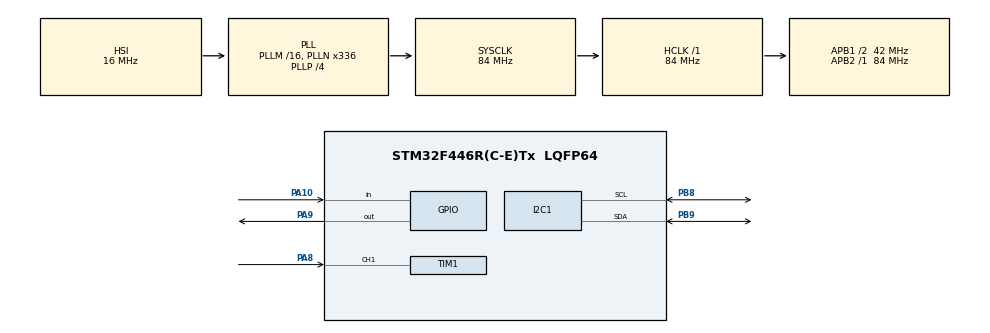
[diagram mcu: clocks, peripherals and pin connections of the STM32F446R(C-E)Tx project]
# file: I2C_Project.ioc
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FREERTOS.Mutexes01=I2CMutex,Dynamic,NULL
FREERTOS.Tasks01=defaultTask,0,128,StartDefaultTask,Default,NULL,Dynamic,NULL,NULL;IrReadTask,0,128,IRTask_Start,Default,NULL,Dynamic,NULL,NULL;I2CSendTask,-3,128,I2CSendTask_Start,Default,NULL,Dynamic,NULL,NULL
I2C1.OwnAddress=0x10
Mcu.Family=STM32F4
Mcu.Name=STM32F446R(C-E)Tx
Mcu.Package=LQFP64
NVIC.I2C1_ER_IRQn=true\:5\:0\:false\:false\:true\:true\:true\:true
NVIC.I2C1_EV_IRQn=true\:5\:0\:false\:false\:true\:true\:true\:true
NVIC.PriorityGroup=NVIC_PRIORITYGROUP_4
NVIC.TIM1_CC_IRQn=true\:5\:0\:false\:false\:true\:true\:true\:true
NVIC.TIM2_IRQn=true\:15\:0\:false\:false\:true\:false\:false\:true
NVIC.TimeBase=TIM2_IRQn
NVIC.TimeBaseIP=TIM2
PA10.Signal=GPIO_Input
PA13.GPIO_Label=TMS
PA13.Mode=Serial_Wire
PA13.Signal=SYS_JTMS-SWDIO
PA14.GPIO_Label=TCK
PA14.Mode=Serial_Wire
PA14.Signal=SYS_JTCK-SWCLK
PA2.GPIO_Label=USART_TX
PA2.Signal=USART2_TX
PA3.GPIO_Label=USART_RX
PA3.Signal=USART2_RX
PA8.Signal=S_TIM1_CH1
PA9.Signal=GPIO_Output
PB3.GPIO_Label=SWO
PB3.Signal=SYS_JTDO-SWO
PB8.Mode=I2C
PB8.Signal=I2C1_SCL
PB9.Mode=I2C
PB9.Signal=I2C1_SDA
PC14-OSC32_IN.Mode=LSE-External-Oscillator
PC14-OSC32_IN.Signal=RCC_OSC32_IN
PC15-OSC32_OUT.Mode=LSE-External-Oscillator
PC15-OSC32_OUT.Signal=RCC_OSC32_OUT
PH0-OSC_IN.Mode=HSE-External-Oscillator
PH0-OSC_IN.Signal=RCC_OSC_IN
PH1-OSC_OUT.Mode=HSE-External-Oscillator
PH1-OSC_OUT.Signal=RCC_OSC_OUT
ProjectManager.HeapSize=0x200
ProjectManager.StackSize=0x400
ProjectManager.TargetToolchain=STM32CubeIDE
RCC.AHBFreq_Value=84000000
RCC.APB1CLKDivider=RCC_HCLK_DIV2
RCC.APB1Freq_Value=42000000
RCC.APB1TimFreq_Value=84000000
RCC.APB2Freq_Value=84000000
RCC.APB2TimFreq_Value=84000000
RCC.CortexFreq_Value=84000000
RCC.FLatency-AdvancedSettings=FLASH_LATENCY_2
RCC.HCLKFreq_Value=84000000
RCC.HSE_VALUE=8000000
RCC.HSI_VALUE=16000000
RCC.PLLN=336
RCC.PLLP=RCC_PLLP_DIV4
RCC.SYSCLKFreq_VALUE=84000000
RCC.SYSCLKSource=RCC_SYSCLKSOURCE_PLLCLK
RCC.USBFreq_Value=168000000
RCC.VCOOutputFreq_Value=336000000
SH.S_TIM1_CH1.0=TIM1_CH1,Input_Capture1_from_TI1
TIM1.Channel-Input_Capture1_from_TI1=TIM_CHANNEL_1
TIM1.Prescaler=84
VP_FREERTOS_VS_CMSIS_V1.Mode=CMSIS_V1
VP_SYS_VS_tim2.Mode=TIM2
board=NUCLEO-F446RE

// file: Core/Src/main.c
#include "main.h"
#include "cmsis_os.h"

I2C_HandleTypeDef hi2c1;

TIM_HandleTypeDef htim1;

osThreadId defaultTaskHandle;
osThreadId IrReadTaskHandle;
osThreadId I2CSendTaskHandle;
osMutexId I2CMutexHandle;

#define TXBUFSIZE 1
volatile uint8_t rx_buf;
uint8_t tx_buf=0;

HAL_StatusTypeDef sig = 0x0;
void ResetI2C(I2C_HandleTypeDef* rev_i2c)
{
	HAL_I2C_DeInit(rev_i2c);
	HAL_I2C_Init(rev_i2c);
}

void SystemClock_Config(void);
static void MX_GPIO_Init(void);
static void MX_I2C1_Init(void);
static void MX_TIM1_Init(void);
void StartDefaultTask(void const * argument);
void IRTask_Start(void const * argument);
void I2CSendTask_Start(void const * argument);

int main(void)
{

  HAL_Init();

  SystemClock_Config();

  MX_GPIO_Init();
  MX_I2C1_Init();
  MX_TIM1_Init();

  osMutexDef(I2CMutex);
  I2CMutexHandle = osMutexCreate(osMutex(I2CMutex));

  osThreadDef(defaultTask, StartDefaultTask, osPriorityNormal, 0, 128);
  defaultTaskHandle = osThreadCreate(osThread(defaultTask), NULL);

  /* definition and creation of IrReadTask */
  osThreadDef(IrReadTask, IRTask_Start, osPriorityNormal, 0, 128);
  IrReadTaskHandle = osThreadCreate(osThread(IrReadTask), NULL);

  /* definition and creation of I2CSendTask */
  osThreadDef(I2CSendTask, I2CSendTask_Start, osPriorityNormal, 0, 128);
  I2CSendTaskHandle = osThreadCreate(osThread(I2CSendTask), NULL);

  /* Start scheduler */
  osKernelStart();

  while (1)
  {

  }

}

void SystemClock_Config(void)
{
  RCC_OscInitTypeDef RCC_OscInitStruct = {0};
  RCC_ClkInitTypeDef RCC_ClkInitStruct = {0};

  /** Configure the main internal regulator output voltage
  */
  __HAL_RCC_PWR_CLK_ENABLE();
  __HAL_PWR_VOLTAGESCALING_CONFIG(PWR_REGULATOR_VOLTAGE_SCALE3);
  /** Initializes the RCC Oscillators according to the specified parameters
  * in the RCC_OscInitTypeDef structure.
  */
  RCC_OscInitStruct.OscillatorType = RCC_OSCILLATORTYPE_HSI;
  RCC_OscInitStruct.HSIState = RCC_HSI_ON;
  RCC_OscInitStruct.HSICalibrationValue = RCC_HSICALIBRATION_DEFAULT;
  RCC_OscInitStruct.PLL.PLLState = RCC_PLL_ON;
  RCC_OscInitStruct.PLL.PLLSource = RCC_PLLSOURCE_HSI;
  RCC_OscInitStruct.PLL.PLLM = 16;
  RCC_OscInitStruct.PLL.PLLN = 336;
  RCC_OscInitStruct.PLL.PLLP = RCC_PLLP_DIV4;
  RCC_OscInitStruct.PLL.PLLQ = 2;
  RCC_OscInitStruct.PLL.PLLR = 2;
  if (HAL_RCC_OscConfig(&RCC_OscInitStruct) != HAL_OK)
  {
    Error_Handler();
  }
  /** Initializes the CPU, AHB and APB buses clocks
  */
  RCC_ClkInitStruct.ClockType = RCC_CLOCKTYPE_HCLK|RCC_CLOCKTYPE_SYSCLK
                              |RCC_CLOCKTYPE_PCLK1|RCC_CLOCKTYPE_PCLK2;
  RCC_ClkInitStruct.SYSCLKSource = RCC_SYSCLKSOURCE_PLLCLK;
  RCC_ClkInitStruct.AHBCLKDivider = RCC_SYSCLK_DIV1;
  RCC_ClkInitStruct.APB1CLKDivider = RCC_HCLK_DIV2;
  RCC_ClkInitStruct.APB2CLKDivider = RCC_HCLK_DIV1;

  if (HAL_RCC_ClockConfig(&RCC_ClkInitStruct, FLASH_LATENCY_2) != HAL_OK)
  {
    Error_Handler();
  }
}

static void MX_I2C1_Init(void)
{

  hi2c1.Instance = I2C1;
  hi2c1.Init.ClockSpeed = 100000;
  hi2c1.Init.DutyCycle = I2C_DUTYCYCLE_2;
  hi2c1.Init.OwnAddress1 = 32;
  hi2c1.Init.AddressingMode = I2C_ADDRESSINGMODE_7BIT;
  hi2c1.Init.DualAddressMode = I2C_DUALADDRESS_DISABLE;
  hi2c1.Init.OwnAddress2 = 0;
  hi2c1.Init.GeneralCallMode = I2C_GENERALCALL_DISABLE;
  hi2c1.Init.NoStretchMode = I2C_NOSTRETCH_DISABLE;
  if (HAL_I2C_Init(&hi2c1) != HAL_OK)
  {
    Error_Handler();
  }

}

static void MX_TIM1_Init(void)
{

  TIM_MasterConfigTypeDef sMasterConfig = {0};
  TIM_IC_InitTypeDef sConfigIC = {0};

  htim1.Instance = TIM1;
  htim1.Init.Prescaler = 84;
  htim1.Init.CounterMode = TIM_COUNTERMODE_UP;
  htim1.Init.Period = 65535;
  htim1.Init.ClockDivision = TIM_CLOCKDIVISION_DIV1;
  htim1.Init.RepetitionCounter = 0;
  htim1.Init.AutoReloadPreload = TIM_AUTORELOAD_PRELOAD_DISABLE;
  if (HAL_TIM_IC_Init(&htim1) != HAL_OK)
  {
    Error_Handler();
  }
  sMasterConfig.MasterOutputTrigger = TIM_TRGO_RESET;
  sMasterConfig.MasterSlaveMode = TIM_MASTERSLAVEMODE_DISABLE;
  if (HAL_TIMEx_MasterConfigSynchronization(&htim1, &sMasterConfig) != HAL_OK)
  {
    Error_Handler();
  }
  sConfigIC.ICPolarity = TIM_INPUTCHANNELPOLARITY_RISING;
  sConfigIC.ICSelection = TIM_ICSELECTION_DIRECTTI;
  sConfigIC.ICPrescaler = TIM_ICPSC_DIV1;
  sConfigIC.ICFilter = 0;
  if (HAL_TIM_IC_ConfigChannel(&htim1, &sConfigIC, TIM_CHANNEL_1) != HAL_OK)
  {
    Error_Handler();
  }

}

static void MX_GPIO_Init(void)
{
  GPIO_InitTypeDef GPIO_InitStruct = {0};

  /* GPIO Ports Clock Enable */
  __HAL_RCC_GPIOC_CLK_ENABLE();
  __HAL_RCC_GPIOH_CLK_ENABLE();
  __HAL_RCC_GPIOA_CLK_ENABLE();
  __HAL_RCC_GPIOB_CLK_ENABLE();

  /*Configure GPIO pin Output Level */
  HAL_GPIO_WritePin(GPIOA, GPIO_PIN_9, GPIO_PIN_RESET);

  /*Configure GPIO pins : USART_TX_Pin USART_RX_Pin */
  GPIO_InitStruct.Pin = USART_TX_Pin|USART_RX_Pin;
  GPIO_InitStruct.Mode = GPIO_MODE_AF_PP;
  GPIO_InitStruct.Pull = GPIO_NOPULL;
  GPIO_InitStruct.Speed = GPIO_SPEED_FREQ_VERY_HIGH;
  GPIO_InitStruct.Alternate = GPIO_AF7_USART2;
  HAL_GPIO_Init(GPIOA, &GPIO_InitStruct);

  /*Configure GPIO pin : PA9 */
  GPIO_InitStruct.Pin = GPIO_PIN_9;
  GPIO_InitStruct.Mode = GPIO_MODE_OUTPUT_PP;
  GPIO_InitStruct.Pull = GPIO_NOPULL;
  GPIO_InitStruct.Speed = GPIO_SPEED_FREQ_LOW;
  HAL_GPIO_Init(GPIOA, &GPIO_InitStruct);

  /*Configure GPIO pin : PA10 */
  GPIO_InitStruct.Pin = GPIO_PIN_10;
  GPIO_InitStruct.Mode = GPIO_MODE_INPUT;
  GPIO_InitStruct.Pull = GPIO_NOPULL;
  HAL_GPIO_Init(GPIOA, &GPIO_InitStruct);

}

/* USER CODE END Header_StartDefaultTask */
void StartDefaultTask(void const * argument)
{
  for(;;)
  {
    osDelay(1);
  }
}

void IRTask_Start(void const * argument)
{
  HAL_TIM_IC_Start_IT(&htim1, TIM_CHANNEL_1);
  for(;;)
  {
	  xSemaphoreTake(I2CMutexHandle,portMAX_DELAY);
	  if(HAL_GPIO_ReadPin(GPIOA, GPIO_PIN_10))
	  {
		tx_buf=0;
	  }
	  else
	  {
		  tx_buf=1;
	  }
	  xSemaphoreGive(I2CMutexHandle);
    osDelay(20);
  }
  /* USER CODE END IRTask_Start */
}

void I2CSendTask_Start(void const * argument)
{
  /* USER CODE BEGIN I2CSendTask_Start */
  /* Infinite loop */
  for(;;)
  {
	if ((sig = HAL_I2C_Slave_Receive(&hi2c1, (uint8_t*)&rx_buf, TXBUFSIZE, 0xFFFFFFFF))!=HAL_OK)
	{
		ResetI2C(&hi2c1);
	}
	if ((sig == HAL_OK))
	{
		if((sig = HAL_I2C_Slave_Transmit(&hi2c1, (uint8_t*)&tx_buf, TXBUFSIZE, 0x01))!=HAL_OK)
		{
			ResetI2C(&hi2c1);
		}
		else if (rx_buf == 0x02)
		{
			rx_buf = 0;
			xSemaphoreTake(I2CMutexHandle,portMAX_DELAY);
			HAL_I2C_Slave_Transmit(&hi2c1, (uint8_t*)&tx_buf, TXBUFSIZE, 0x01);
			xSemaphoreGive(I2CMutexHandle);
		}
	}
    osDelay(20);
  }
  /* USER CODE END I2CSendTask_Start */
}

void HAL_TIM_PeriodElapsedCallback(TIM_HandleTypeDef *htim)
{
  if (htim->Instance == TIM2) {
    HAL_IncTick();
  }
}

void Error_Handler(void)
{
  __disable_irq();
  while (1)
  {
  }
}
